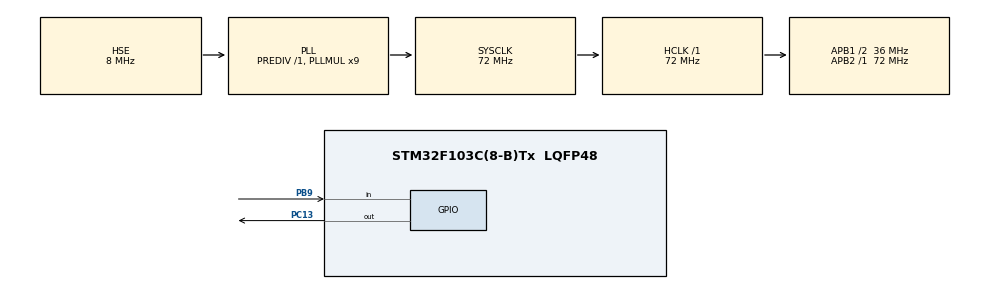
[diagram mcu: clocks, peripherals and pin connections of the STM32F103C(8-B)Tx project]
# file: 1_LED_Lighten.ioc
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Mcu.Family=STM32F1
Mcu.Name=STM32F103C(8-B)Tx
Mcu.Package=LQFP48
NVIC.PriorityGroup=NVIC_PRIORITYGROUP_4
NVIC.TIM3_IRQn=true\:0\:0\:false\:false\:true\:true\:true\:true
NVIC.TIM4_IRQn=true\:1\:0\:true\:false\:true\:true\:true\:true
PA13.Mode=Serial_Wire
PA13.Signal=SYS_JTMS-SWDIO
PA14.Mode=Serial_Wire
PA14.Signal=SYS_JTCK-SWCLK
PB9.GPIO_PuPd=GPIO_PULLUP
PB9.Signal=GPIO_Input
PC13-TAMPER-RTC.PinState=GPIO_PIN_SET
PC13-TAMPER-RTC.Signal=GPIO_Output
PD0-OSC_IN.Mode=HSE-External-Oscillator
PD0-OSC_IN.Signal=RCC_OSC_IN
PD1-OSC_OUT.Mode=HSE-External-Oscillator
PD1-OSC_OUT.Signal=RCC_OSC_OUT
ProjectManager.HeapSize=0x200
ProjectManager.StackSize=0x400
ProjectManager.TargetToolchain=Makefile
RCC.AHBFreq_Value=72000000
RCC.APB1CLKDivider=RCC_HCLK_DIV2
RCC.APB1Freq_Value=36000000
RCC.APB1TimFreq_Value=72000000
RCC.APB2Freq_Value=72000000
RCC.APB2TimFreq_Value=72000000
RCC.HCLKFreq_Value=72000000
RCC.PLLMUL=RCC_PLL_MUL9
RCC.PLLSourceVirtual=RCC_PLLSOURCE_HSE
RCC.SYSCLKFreq_VALUE=72000000
RCC.SYSCLKSource=RCC_SYSCLKSOURCE_PLLCLK
RCC.USBFreq_Value=72000000
TIM3.AutoReloadPreload=TIM_AUTORELOAD_PRELOAD_ENABLE
TIM3.Period=1000-1
TIM3.Prescaler=72-1
TIM4.AutoReloadPreload=TIM_AUTORELOAD_PRELOAD_ENABLE
TIM4.Period=10000-1
TIM4.Prescaler=1800-1
VP_TIM3_VS_ClockSourceINT.Mode=Internal
VP_TIM4_VS_ClockSourceINT.Mode=Internal
board=custom

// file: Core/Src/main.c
/* USER CODE BEGIN Header */
/**
  ******************************************************************************
  * @file           : main.c
  * @brief          : Main program body
  ******************************************************************************
  * @attention
  *
  * Copyright (c) 2026 STMicroelectronics.
  * All rights reserved.
  *
  * This software is licensed under terms that can be found in the LICENSE file
  * in the root directory of this software component.
  * If no LICENSE file comes with this software, it is provided AS-IS.
  *
  ******************************************************************************
  */
/* USER CODE END Header */
#include "main.h"
#include "tim.h"
#include "gpio.h"

/* USER CODE BEGIN Includes */
#define STABLE_COUNTER 20
/* USER CODE END Includes */

void SystemClock_Config(void);

/* USER CODE BEGIN 0 */
void button_scan();
void change_period();
// int a;
/* USER CODE END 0 */

int main(void)
{

  /* MCU Configuration--------------------------------------------------------*/

  /* Reset of all peripherals, Initializes the Flash interface and the Systick. */
  HAL_Init();

  /* Configure the system clock */
  SystemClock_Config();

  /* Initialize all configured peripherals */
  MX_GPIO_Init();
  MX_TIM4_Init();
  MX_TIM3_Init();
  /* USER CODE BEGIN 2 */
  HAL_TIM_Base_Start_IT(&htim4);
  HAL_TIM_Base_Start_IT(&htim3);
  /* USER CODE END 2 */

  /* Infinite loop */
  while (1)
  {

    /* USER CODE BEGIN 3 */
    // a=HAL_GPIO_ReadPin(GPIOB,GPIO_PIN_9);
  }
  /* USER CODE END 3 */
}

void SystemClock_Config(void)
{
  RCC_OscInitTypeDef RCC_OscInitStruct = {0};
  RCC_ClkInitTypeDef RCC_ClkInitStruct = {0};

  /** Initializes the RCC Oscillators according to the specified parameters
  * in the RCC_OscInitTypeDef structure.
  */
  RCC_OscInitStruct.OscillatorType = RCC_OSCILLATORTYPE_HSE;
  RCC_OscInitStruct.HSEState = RCC_HSE_ON;
  RCC_OscInitStruct.HSEPredivValue = RCC_HSE_PREDIV_DIV1;
  RCC_OscInitStruct.HSIState = RCC_HSI_ON;
  RCC_OscInitStruct.PLL.PLLState = RCC_PLL_ON;
  RCC_OscInitStruct.PLL.PLLSource = RCC_PLLSOURCE_HSE;
  RCC_OscInitStruct.PLL.PLLMUL = RCC_PLL_MUL9;
  if (HAL_RCC_OscConfig(&RCC_OscInitStruct) != HAL_OK)
  {
    Error_Handler();
  }

  /** Initializes the CPU, AHB and APB buses clocks
  */
  RCC_ClkInitStruct.ClockType = RCC_CLOCKTYPE_HCLK|RCC_CLOCKTYPE_SYSCLK
                              |RCC_CLOCKTYPE_PCLK1|RCC_CLOCKTYPE_PCLK2;
  RCC_ClkInitStruct.SYSCLKSource = RCC_SYSCLKSOURCE_PLLCLK;
  RCC_ClkInitStruct.AHBCLKDivider = RCC_SYSCLK_DIV1;
  RCC_ClkInitStruct.APB1CLKDivider = RCC_HCLK_DIV2;
  RCC_ClkInitStruct.APB2CLKDivider = RCC_HCLK_DIV1;

  if (HAL_RCC_ClockConfig(&RCC_ClkInitStruct, FLASH_LATENCY_2) != HAL_OK)
  {
    Error_Handler();
  }
}

/* USER CODE BEGIN 4 */
int period_num=2; //period_num * 250ms为周期，初始0.5s改变状态
int current_period=0;

void change_period()
{
  period_num++;
  current_period=0;
  if(period_num>3){
    period_num=1;
  }
}

void HAL_TIM_PeriodElapsedCallback(TIM_HandleTypeDef *htim)
{
  if(htim->Instance==TIM4){
    if(period_num==current_period){
      HAL_GPIO_TogglePin(GPIOC,GPIO_PIN_13);
      current_period=0; //复位计数器
    }
    current_period++;
  }
  if(htim->Instance==TIM3){
    button_scan();
  }
}

int count=0; //计数器
int last_status=1; //原本状态
int now_status=1; //当前状态

void button_scan()
{
  now_status=HAL_GPIO_ReadPin(GPIOB,GPIO_PIN_9);
  if(now_status!=last_status){ //状态改变
    count++;
    if(count>=STABLE_COUNTER){ //达到稳定阈值
      count=0; //复位计数器
      //按键状态改变
      if(last_status==1){ //按下
        change_period();
      }
      last_status=!last_status;
    }
  }else{
    count=0; //二者一致则清空计数器
  }
}

/* USER CODE END 4 */

void Error_Handler(void)
{
  __disable_irq();
  while (1)
  {
  }
}
